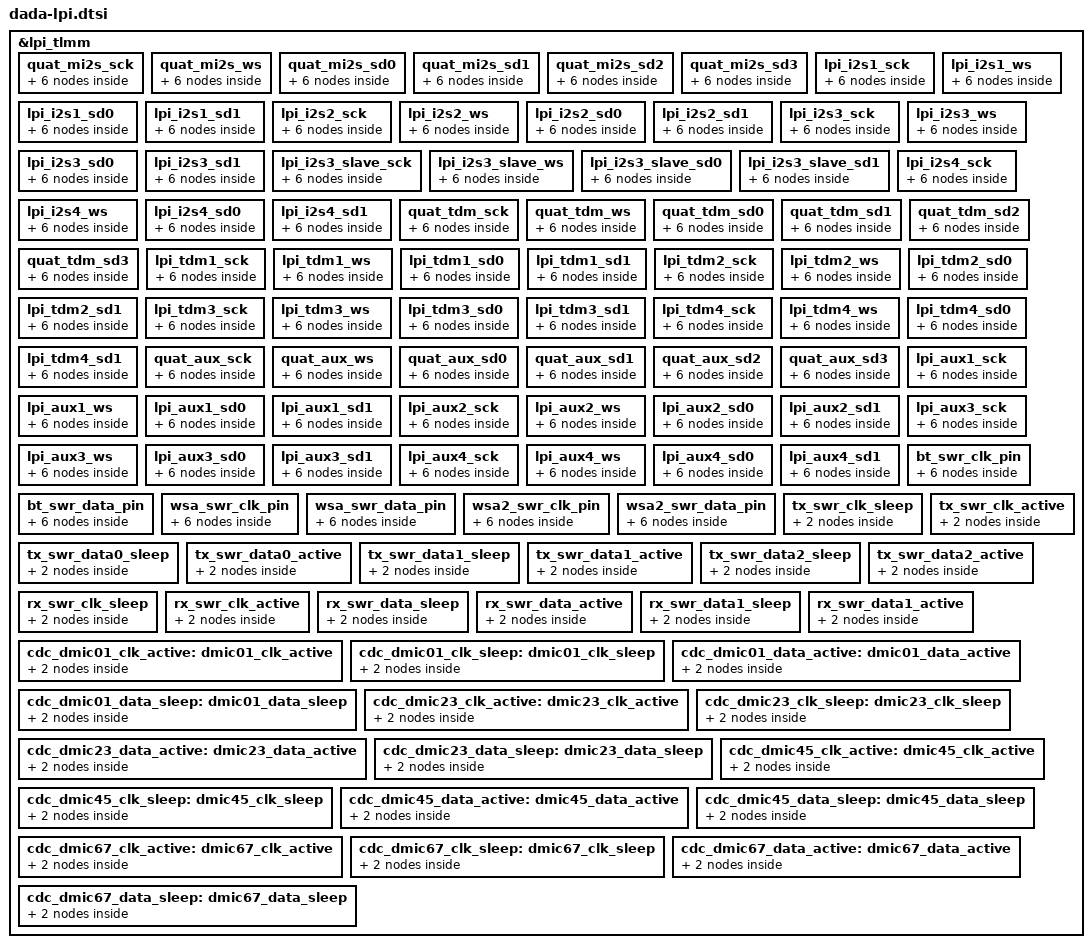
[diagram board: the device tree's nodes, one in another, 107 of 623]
// SPDX-License-Identifier: BSD-3-Clause
/*
 * Copyright (c) 2023-2024 Qualcomm Innovation Center, Inc. All rights reserved.
 * Copyright (c) 2025 The LineageOS Project
 */

&lpi_tlmm {
	quat_mi2s_sck {

		quat_mi2s_sck_sleep: quat_mi2s_sck_sleep {

			mux {
				function = "func2";
				pins = "gpio0";
			};

			config {
				input-enable;
				bias-pull-down;
				drive-strength = <0x02>;
				pins = "gpio0";
			};
		};

		quat_mi2s_sck_active: quat_mi2s_sck_active {

			mux {
				function = "func2";
				pins = "gpio0";
			};

			config {
				output-high;
				bias-disable;
				drive-strength = <0x08>;
				pins = "gpio0";
			};
		};
	};

	quat_mi2s_ws {

		quat_mi2s_ws_sleep: quat_mi2s_ws_sleep {

			mux {
				function = "func2";
				pins = "gpio1";
			};

			config {
				input-enable;
				bias-pull-down;
				drive-strength = <0x02>;
				pins = "gpio1";
			};
		};

		quat_mi2s_ws_active: quat_mi2s_ws_active {

			mux {
				function = "func2";
				pins = "gpio1";
			};

			config {
				output-high;
				bias-disable;
				drive-strength = <0x08>;
				pins = "gpio1";
			};
		};
	};

	quat_mi2s_sd0 {

		quat_mi2s_sd0_sleep: quat_mi2s_sd0_sleep {

			mux {
				function = "func2";
				pins = "gpio2";
			};

			config {
				input-enable;
				bias-pull-down;
				drive-strength = <0x02>;
				pins = "gpio2";
			};
		};

		quat_mi2s_sd0_active: quat_mi2s_sd0_active {

			mux {
				function = "func2";
				pins = "gpio2";
			};

			config {
				output-high;
				bias-disable;
				drive-strength = <0x08>;
				pins = "gpio2";
			};
		};
	};

	quat_mi2s_sd1 {

		quat_mi2s_sd1_sleep: quat_mi2s_sd1_sleep {

			mux {
				function = "func2";
				pins = "gpio3";
			};

			config {
				input-enable;
				bias-pull-down;
				drive-strength = <0x02>;
				pins = "gpio3";
			};
		};

		quat_mi2s_sd1_active: quat_mi2s_sd1_active {

			mux {
				function = "func2";
				pins = "gpio3";
			};

			config {
				output-high;
				bias-disable;
				drive-strength = <0x08>;
				pins = "gpio3";
			};
		};
	};

	quat_mi2s_sd2 {

		quat_mi2s_sd2_sleep: quat_mi2s_sd2_sleep {

			mux {
				function = "func2";
				pins = "gpio4";
			};

			config {
				input-enable;
				bias-pull-down;
				drive-strength = <0x02>;
				pins = "gpio4";
			};
		};

		quat_mi2s_sd2_active: quat_mi2s_sd2_active {

			mux {
				function = "func2";
				pins = "gpio4";
			};

			config {
				output-high;
				bias-disable;
				drive-strength = <0x08>;
				pins = "gpio4";
			};
		};
	};

	quat_mi2s_sd3 {

		quat_mi2s_sd3_sleep: quat_mi2s_sd3_sleep {

			mux {
				function = "func3";
				pins = "gpio5";
			};

			config {
				input-enable;
				bias-pull-down;
				drive-strength = <0x02>;
				pins = "gpio5";
			};
		};

		quat_mi2s_sd3_active: quat_mi2s_sd3_active {

			mux {
				function = "func3";
				pins = "gpio5";
			};

			config {
				output-high;
				bias-disable;
				drive-strength = <0x08>;
				pins = "gpio5";
			};
		};
	};

	lpi_i2s1_sck {

		lpi_i2s1_sck_sleep: lpi_i2s1_sck_sleep {

			mux {
				function = "func2";
				pins = "gpio6";
			};

			config {
				input-enable;
				bias-pull-down;
				drive-strength = <0x02>;
				pins = "gpio6";
			};
		};

		lpi_i2s1_sck_active: lpi_i2s1_sck_active {

			mux {
				function = "func2";
				pins = "gpio6";
			};

			config {
				output-high;
				bias-disable;
				drive-strength = <0x08>;
				pins = "gpio6";
			};
		};
	};

	lpi_i2s1_ws {

		lpi_i2s1_ws_sleep: lpi_i2s1_ws_sleep {

			mux {
				function = "func2";
				pins = "gpio7";
			};

			config {
				input-enable;
				bias-pull-down;
				drive-strength = <0x02>;
				pins = "gpio7";
			};
		};

		lpi_i2s1_ws_active: lpi_i2s1_ws_active {

			mux {
				function = "func2";
				pins = "gpio7";
			};

			config {
				output-high;
				bias-disable;
				drive-strength = <0x08>;
				pins = "gpio7";
			};
		};
	};

	lpi_i2s1_sd0 {

		lpi_i2s1_sd0_sleep: lpi_i2s1_sd0_sleep {

			mux {
				function = "func2";
				pins = "gpio8";
			};

			config {
				input-enable;
				bias-pull-down;
				drive-strength = <0x02>;
				pins = "gpio8";
			};
		};

		lpi_i2s1_sd0_active: lpi_i2s1_sd0_active {

			mux {
				function = "func2";
				pins = "gpio8";
			};

			config {
				output-high;
				bias-disable;
				drive-strength = <0x08>;
				pins = "gpio8";
			};
		};
	};

	lpi_i2s1_sd1 {

		lpi_i2s1_sd1_sleep: lpi_i2s1_sd1_sleep {

			mux {
				function = "func2";
				pins = "gpio9";
			};

			config {
				input-enable;
				bias-pull-down;
				drive-strength = <0x02>;
				pins = "gpio9";
			};
		};

		lpi_i2s1_sd1_active: lpi_i2s1_sd1_active {

			mux {
				function = "func2";
				pins = "gpio9";
			};

			config {
				output-high;
				bias-disable;
				drive-strength = <0x08>;
				pins = "gpio9";
			};
		};
	};

	lpi_i2s2_sck {

		lpi_i2s2_sck_sleep: lpi_i2s2_sck_sleep {

			mux {
				function = "func1";
				pins = "gpio10";
			};

			config {
				input-enable;
				bias-pull-down;
				drive-strength = <0x02>;
				pins = "gpio10";
			};
		};

		lpi_i2s2_sck_active: lpi_i2s2_sck_active {

			mux {
				function = "func1";
				pins = "gpio10";
			};

			config {
				output-high;
				bias-disable;
				drive-strength = <0x08>;
				pins = "gpio10";
			};
		};
	};

	lpi_i2s2_ws {

		lpi_i2s2_ws_sleep: lpi_i2s2_ws_sleep {

			mux {
				function = "func1";
				pins = "gpio11";
			};

			config {
				input-enable;
				bias-pull-down;
				drive-strength = <0x02>;
				pins = "gpio11";
			};
		};

		lpi_i2s2_ws_active: lpi_i2s2_ws_active {

			mux {
				function = "func1";
				pins = "gpio11";
			};

			config {
				output-high;
				bias-disable;
				drive-strength = <0x08>;
				pins = "gpio11";
			};
		};
	};

	lpi_i2s2_sd0 {

		lpi_i2s2_sd0_sleep: lpi_i2s2_sd0_sleep {

			mux {
				function = "func1";
				pins = "gpio15";
			};

			config {
				input-enable;
				bias-pull-down;
				drive-strength = <0x02>;
				pins = "gpio15";
			};
		};

		lpi_i2s2_sd0_active: lpi_i2s2_sd0_active {

			mux {
				function = "func1";
				pins = "gpio15";
			};

			config {
				output-high;
				bias-disable;
				drive-strength = <0x08>;
				pins = "gpio15";
			};
		};
	};

	lpi_i2s2_sd1 {

		lpi_i2s2_sd1_sleep: lpi_i2s2_sd1_sleep {

			mux {
				function = "func1";
				pins = "gpio16";
			};

			config {
				input-enable;
				bias-pull-down;
				drive-strength = <0x02>;
				pins = "gpio16";
			};
		};

		lpi_i2s2_sd1_active: lpi_i2s2_sd1_active {

			mux {
				function = "func1";
				pins = "gpio16";
			};

			config {
				output-high;
				bias-disable;
				drive-strength = <0x08>;
				pins = "gpio16";
			};
		};
	};

	lpi_i2s3_sck {

		lpi_i2s3_sck_sleep: lpi_i2s3_sck_sleep {

			mux {
				function = "func2";
				pins = "gpio12";
			};

			config {
				input-enable;
				bias-pull-down;
				drive-strength = <0x02>;
				pins = "gpio12";
			};
		};

		lpi_i2s3_sck_active: lpi_i2s3_sck_active {

			mux {
				function = "func2";
				pins = "gpio12";
			};

			config {
				output-high;
				bias-disable;
				drive-strength = <0x08>;
				pins = "gpio12";
			};
		};
	};

	lpi_i2s3_ws {

		lpi_i2s3_ws_sleep: lpi_i2s3_ws_sleep {

			mux {
				function = "func2";
				pins = "gpio13";
			};

			config {
				input-enable;
				bias-pull-down;
				drive-strength = <0x02>;
				pins = "gpio13";
			};
		};

		lpi_i2s3_ws_active: lpi_i2s3_ws_active {

			mux {
				function = "func2";
				pins = "gpio13";
			};

			config {
				output-high;
				bias-disable;
				drive-strength = <0x08>;
				pins = "gpio13";
			};
		};
	};

	lpi_i2s3_sd0 {

		lpi_i2s3_sd0_sleep: lpi_i2s3_sd0_sleep {

			mux {
				function = "func2";
				pins = "gpio17";
			};

			config {
				input-enable;
				bias-pull-down;
				drive-strength = <0x02>;
				pins = "gpio17";
			};
		};

		lpi_i2s3_sd0_active: lpi_i2s3_sd0_active {

			mux {
				function = "func2";
				pins = "gpio17";
			};

			config {
				output-high;
				bias-disable;
				drive-strength = <0x08>;
				pins = "gpio17";
			};
		};
	};

	lpi_i2s3_sd1 {

		lpi_i2s3_sd1_sleep: lpi_i2s3_sd1_sleep {

			mux {
				function = "func2";
				pins = "gpio18";
			};

			config {
				input-enable;
				bias-pull-down;
				drive-strength = <0x02>;
				pins = "gpio18";
			};
		};

		lpi_i2s3_sd1_active: lpi_i2s3_sd1_active {

			mux {
				function = "func2";
				pins = "gpio18";
			};

			config {
				output-high;
				bias-disable;
				drive-strength = <0x08>;
				pins = "gpio18";
			};
		};
	};

	lpi_i2s3_slave_sck {

		lpi_i2s3_slave_sck_sleep: lpi_i2s3_slave_sck_sleep {

			mux {
				function = "func2";
				pins = "gpio12";
			};

			config {
				input-enable;
				bias-pull-down;
				drive-strength = <0x02>;
				pins = "gpio12";
			};
		};

		lpi_i2s3_slave_sck_active: lpi_i2s3_slave_sck_active {

			mux {
				function = "func2";
				pins = "gpio12";
			};

			config {
				input-enable;
				bias-disable;
				drive-strength = <0x08>;
				pins = "gpio12";
			};
		};
	};

	lpi_i2s3_slave_ws {

		lpi_i2s3_slave_ws_sleep: lpi_i2s3_slave_ws_sleep {

			mux {
				function = "func2";
				pins = "gpio13";
			};

			config {
				input-enable;
				bias-pull-down;
				drive-strength = <0x02>;
				pins = "gpio13";
			};
		};

		lpi_i2s3_slave_ws_active: lpi_i2s3_slave_ws_active {

			mux {
				function = "func2";
				pins = "gpio13";
			};

			config {
				input-enable;
				bias-disable;
				drive-strength = <0x08>;
				pins = "gpio13";
			};
		};
	};

	lpi_i2s3_slave_sd0 {

		lpi_i2s3_slave_sd0_sleep: lpi_i2s3_slave_sd0_sleep {

			mux {
				function = "func2";
				pins = "gpio17";
			};

			config {
				input-enable;
				bias-pull-down;
				drive-strength = <0x02>;
				pins = "gpio17";
			};
		};

		lpi_i2s3_slave_sd0_active: lpi_i2s3_slave_sd0_active {

			mux {
				function = "func2";
				pins = "gpio17";
			};

			config {
				input-enable;
				bias-disable;
				drive-strength = <0x08>;
				pins = "gpio17";
			};
		};
	};

	lpi_i2s3_slave_sd1 {

		lpi_i2s3_slave_sd1_sleep: lpi_i2s3_slave_sd1_sleep {

			mux {
				function = "func2";
				pins = "gpio18";
			};

			config {
				input-enable;
				bias-pull-down;
				drive-strength = <0x02>;
				pins = "gpio18";
			};
		};

		lpi_i2s3_slave_sd1_active: lpi_i2s3_slave_sd1_active {

			mux {
				function = "func2";
				pins = "gpio18";
			};

			config {
				output-high;
				bias-disable;
				drive-strength = <0x08>;
				pins = "gpio18";
			};
		};
	};

	lpi_i2s4_sck {

		lpi_i2s4_sck_sleep: lpi_i2s4_sck_sleep {

			mux {
				function = "func1";
				pins = "gpio19";
			};

			config {
				input-enable;
				bias-pull-down;
				drive-strength = <0x02>;
				pins = "gpio19";
			};
		};

		lpi_i2s4_sck_active: lpi_i2s4_sck_active {

			mux {
				function = "func1";
				pins = "gpio19";
			};

			config {
				output-high;
				bias-disable;
				drive-strength = <0x08>;
				pins = "gpio19";
			};
		};
	};

	lpi_i2s4_ws {

		lpi_i2s4_ws_sleep: lpi_i2s4_ws_sleep {

			mux {
				function = "func1";
				pins = "gpio20";
			};

			config {
				input-enable;
				bias-pull-down;
				drive-strength = <0x02>;
				pins = "gpio20";
			};
		};

		lpi_i2s4_ws_active: lpi_i2s4_ws_active {

			mux {
				function = "func1";
				pins = "gpio20";
			};

			config {
				output-high;
				bias-disable;
				drive-strength = <0x08>;
				pins = "gpio20";
			};
		};
	};

	lpi_i2s4_sd0 {

		lpi_i2s4_sd0_sleep: lpi_i2s4_sd0_sleep {

			mux {
				function = "func1";
				pins = "gpio21";
			};

			config {
				input-enable;
				bias-pull-down;
				drive-strength = <0x02>;
				pins = "gpio21";
			};
		};

		lpi_i2s4_sd0_active: lpi_i2s4_sd0_active {

			mux {
				function = "func1";
				pins = "gpio21";
			};

			config {
				output-high;
				bias-disable;
				drive-strength = <0x08>;
				pins = "gpio21";
			};
		};
	};

	lpi_i2s4_sd1 {

		lpi_i2s4_sd1_sleep: lpi_i2s4_sd1_sleep {

			mux {
				function = "func1";
				pins = "gpio22";
			};

			config {
				input-enable;
				bias-pull-down;
				drive-strength = <0x02>;
				pins = "gpio22";
			};
		};

		lpi_i2s4_sd1_active: lpi_i2s4_sd1_active {

			mux {
				function = "func1";
				pins = "gpio22";
			};

			config {
				output-high;
				bias-disable;
				drive-strength = <0x08>;
				pins = "gpio22";
			};
		};
	};

	quat_tdm_sck {

		quat_tdm_sck_sleep: quat_tdm_sck_sleep {

			mux {
				function = "func2";
				pins = "gpio0";
			};

			config {
				input-enable;
				bias-pull-down;
				drive-strength = <0x02>;
				pins = "gpio0";
			};
		};

		quat_tdm_sck_active: quat_tdm_sck_active {

			mux {
				function = "func2";
				pins = "gpio0";
			};

			config {
				output-high;
				bias-disable;
				drive-strength = <0x08>;
				pins = "gpio0";
			};
		};
	};

	quat_tdm_ws {

		quat_tdm_ws_sleep: quat_tdm_ws_sleep {

			mux {
				function = "func2";
				pins = "gpio1";
			};

			config {
				input-enable;
				bias-pull-down;
				drive-strength = <0x02>;
				pins = "gpio1";
			};
		};

		quat_tdm_ws_active: quat_tdm_ws_active {

			mux {
				function = "func2";
				pins = "gpio1";
			};

			config {
				output-high;
				bias-disable;
				drive-strength = <0x08>;
				pins = "gpio1";
			};
		};
	};

	quat_tdm_sd0 {

		quat_tdm_sd0_sleep: quat_tdm_sd0_sleep {

			mux {
				function = "func2";
				pins = "gpio2";
			};

			config {
				input-enable;
				bias-pull-down;
				drive-strength = <0x02>;
				pins = "gpio2";
			};
		};

		quat_tdm_sd0_active: quat_tdm_sd0_active {

			mux {
				function = "func2";
				pins = "gpio2";
			};

			config {
				output-high;
				bias-disable;
				drive-strength = <0x08>;
				pins = "gpio2";
			};
		};
	};

	quat_tdm_sd1 {

		quat_tdm_sd1_sleep: quat_tdm_sd1_sleep {

			mux {
				function = "func2";
				pins = "gpio3";
			};

			config {
				input-enable;
				bias-pull-down;
				drive-strength = <0x02>;
				pins = "gpio3";
			};
		};

		quat_tdm_sd1_active: quat_tdm_sd1_active {

			mux {
				function = "func2";
				pins = "gpio3";
			};

			config {
				output-high;
				bias-disable;
				drive-strength = <0x08>;
				pins = "gpio3";
			};
		};
	};

	quat_tdm_sd2 {

		quat_tdm_sd2_sleep: quat_tdm_sd2_sleep {

			mux {
				function = "func2";
				pins = "gpio4";
			};

			config {
				input-enable;
				bias-pull-down;
				drive-strength = <0x02>;
				pins = "gpio4";
			};
		};

		quat_tdm_sd2_active: quat_tdm_sd2_active {

			mux {
				function = "func2";
				pins = "gpio4";
			};

			config {
				output-high;
				bias-disable;
				drive-strength = <0x08>;
				pins = "gpio4";
			};
		};
	};

	quat_tdm_sd3 {

		quat_tdm_sd3_sleep: quat_tdm_sd3_sleep {

			mux {
				function = "func3";
				pins = "gpio5";
			};

			config {
				input-enable;
				bias-pull-down;
				drive-strength = <0x02>;
				pins = "gpio5";
			};
		};

		quat_tdm_sd3_active: quat_tdm_sd3_active {

			mux {
				function = "func3";
				pins = "gpio5";
			};

			config {
				output-high;
				bias-disable;
				drive-strength = <0x08>;
				pins = "gpio5";
			};
		};
	};

	lpi_tdm1_sck {

		lpi_tdm1_sck_sleep: lpi_tdm1_sck_sleep {

			mux {
				function = "func2";
				pins = "gpio6";
			};

			config {
				input-enable;
				bias-pull-down;
				drive-strength = <0x02>;
				pins = "gpio6";
			};
		};

		lpi_tdm1_sck_active: lpi_tdm1_sck_active {

			mux {
				function = "func2";
				pins = "gpio6";
			};

			config {
				output-high;
				bias-disable;
				drive-strength = <0x08>;
				pins = "gpio6";
			};
		};
	};

	lpi_tdm1_ws {

		lpi_tdm1_ws_sleep: lpi_tdm1_ws_sleep {

			mux {
				function = "func2";
				pins = "gpio7";
			};

			config {
				input-enable;
				bias-pull-down;
				drive-strength = <0x02>;
				pins = "gpio7";
			};
		};

		lpi_tdm1_ws_active: lpi_tdm1_ws_active {

			mux {
				function = "func2";
				pins = "gpio7";
			};

			config {
				output-high;
				bias-disable;
				drive-strength = <0x08>;
				pins = "gpio7";
			};
		};
	};

	lpi_tdm1_sd0 {

		lpi_tdm1_sd0_sleep: lpi_tdm1_sd0_sleep {

			mux {
				function = "func2";
				pins = "gpio8";
			};

			config {
				input-enable;
				bias-pull-down;
				drive-strength = <0x02>;
				pins = "gpio8";
			};
		};

		lpi_tdm1_sd0_active: lpi_tdm1_sd0_active {

			mux {
				function = "func2";
				pins = "gpio8";
			};

			config {
				output-high;
				bias-disable;
				drive-strength = <0x08>;
				pins = "gpio8";
			};
		};
	};

	lpi_tdm1_sd1 {

		lpi_tdm1_sd1_sleep: lpi_tdm1_sd1_sleep {

			mux {
				function = "func2";
				pins = "gpio9";
			};

			config {
				input-enable;
				bias-pull-down;
				drive-strength = <0x02>;
				pins = "gpio9";
			};
		};

		lpi_tdm1_sd1_active: lpi_tdm1_sd1_active {

			mux {
				function = "func2";
				pins = "gpio9";
			};

			config {
				output-high;
				bias-disable;
				drive-strength = <0x08>;
				pins = "gpio9";
			};
		};
	};

	lpi_tdm2_sck {

		lpi_tdm2_sck_sleep: lpi_tdm2_sck_sleep {

			mux {
				function = "func1";
				pins = "gpio10";
			};

			config {
				input-enable;
				bias-pull-down;
				drive-strength = <0x02>;
				pins = "gpio10";
			};
		};

		lpi_tdm2_sck_active: lpi_tdm2_sck_active {

			mux {
				function = "func1";
				pins = "gpio10";
			};

			config {
				output-high;
				bias-disable;
				drive-strength = <0x08>;
				pins = "gpio10";
			};
		};
	};

	lpi_tdm2_ws {

		lpi_tdm2_ws_sleep: lpi_tdm2_ws_sleep {

			mux {
				function = "func1";
				pins = "gpio11";
			};

			config {
				input-enable;
				bias-pull-down;
				drive-strength = <0x02>;
				pins = "gpio11";
			};
		};

		lpi_tdm2_ws_active: lpi_tdm2_ws_active {

			mux {
				function = "func1";
				pins = "gpio11";
			};

			config {
				output-high;
				bias-disable;
				drive-strength = <0x08>;
				pins = "gpio11";
			};
		};
	};

	lpi_tdm2_sd0 {

		lpi_tdm2_sd0_sleep: lpi_tdm2_sd0_sleep {

			mux {
				function = "func1";
				pins = "gpio15";
			};

			config {
				input-enable;
				bias-pull-down;
				drive-strength = <0x02>;
				pins = "gpio15";
			};
		};

		lpi_tdm2_sd0_active: lpi_tdm2_sd0_active {

			mux {
				function = "func1";
				pins = "gpio15";
			};

			config {
				output-high;
				bias-disable;
				drive-strength = <0x08>;
				pins = "gpio15";
			};
		};
	};

	lpi_tdm2_sd1 {

		lpi_tdm2_sd1_sleep: lpi_tdm2_sd1_sleep {

			mux {
				function = "func1";
				pins = "gpio16";
			};

			config {
				input-enable;
				bias-pull-down;
				drive-strength = <0x02>;
				pins = "gpio16";
			};
		};

		lpi_tdm2_sd1_active: lpi_tdm2_sd1_active {

			mux {
				function = "func1";
				pins = "gpio16";
			};

			config {
				output-high;
				bias-disable;
				drive-strength = <0x08>;
				pins = "gpio16";
			};
		};
	};

	lpi_tdm3_sck {

		lpi_tdm3_sck_sleep: lpi_tdm3_sck_sleep {

			mux {
				function = "func2";
				pins = "gpio12";
			};

			config {
				input-enable;
				bias-pull-down;
				drive-strength = <0x02>;
				pins = "gpio12";
			};
		};

		lpi_tdm3_sck_active: lpi_tdm3_sck_active {

			mux {
				function = "func2";
				pins = "gpio12";
			};

			config {
				output-high;
				bias-disable;
				drive-strength = <0x08>;
				pins = "gpio12";
			};
		};
	};

	lpi_tdm3_ws {

		lpi_tdm3_ws_sleep: lpi_tdm3_ws_sleep {

			mux {
				function = "func2";
				pins = "gpio13";
			};

			config {
				input-enable;
				bias-pull-down;
				drive-strength = <0x02>;
				pins = "gpio13";
			};
		};

		lpi_tdm3_ws_active: lpi_tdm3_ws_active {

			mux {
				function = "func2";
				pins = "gpio13";
			};

			config {
				output-high;
				bias-disable;
				drive-strength = <0x08>;
				pins = "gpio13";
			};
		};
	};

	lpi_tdm3_sd0 {

		lpi_tdm3_sd0_sleep: lpi_tdm3_sd0_sleep {

			mux {
				function = "func2";
				pins = "gpio17";
			};

			config {
				input-enable;
				bias-pull-down;
				drive-strength = <0x02>;
				pins = "gpio17";
			};
		};

		lpi_tdm3_sd0_active: lpi_tdm3_sd0_active {

			mux {
				function = "func2";
				pins = "gpio17";
			};

			config {
				output-high;
				bias-disable;
				drive-strength = <0x08>;
				pins = "gpio17";
			};
		};
	};

	lpi_tdm3_sd1 {

		lpi_tdm3_sd1_sleep: lpi_tdm3_sd1_sleep {

			mux {
				function = "func2";
				pins = "gpio18";
			};

			config {
				input-enable;
				bias-pull-down;
				drive-strength = <0x02>;
				pins = "gpio18";
			};
		};

		lpi_tdm3_sd1_active: lpi_tdm3_sd1_active {

			mux {
				function = "func2";
				pins = "gpio18";
			};

			config {
				output-high;
				bias-disable;
				drive-strength = <0x08>;
				pins = "gpio18";
			};
		};
	};

	lpi_tdm4_sck {

		lpi_tdm4_sck_sleep: lpi_tdm4_sck_sleep {

			mux {
				function = "func1";
				pins = "gpio19";
			};

			config {
				input-enable;
				bias-pull-down;
				drive-strength = <0x02>;
				pins = "gpio19";
			};
		};

		lpi_tdm4_sck_active: lpi_tdm4_sck_active {

			mux {
				function = "func1";
				pins = "gpio19";
			};

			config {
				output-high;
				bias-disable;
				drive-strength = <0x08>;
				pins = "gpio19";
			};
		};
	};

	lpi_tdm4_ws {

		lpi_tdm4_ws_sleep: lpi_tdm4_ws_sleep {

			mux {
				function = "func1";
				pins = "gpio20";
			};

			config {
				input-enable;
				bias-pull-down;
				drive-strength = <0x02>;
				pins = "gpio20";
			};
		};

		lpi_tdm4_ws_active: lpi_tdm4_ws_active {

			mux {
				function = "func1";
				pins = "gpio20";
			};

			config {
				output-high;
				bias-disable;
				drive-strength = <0x08>;
				pins = "gpio20";
			};
		};
	};

	lpi_tdm4_sd0 {

		lpi_tdm4_sd0_sleep: lpi_tdm4_sd0_sleep {

			mux {
				function = "func1";
				pins = "gpio21";
			};

			config {
				input-enable;
				bias-pull-down;
				drive-strength = <0x02>;
				pins = "gpio21";
			};
		};

		lpi_tdm4_sd0_active: lpi_tdm4_sd0_active {

			mux {
				function = "func1";
				pins = "gpio21";
			};

			config {
				output-high;
				bias-disable;
				drive-strength = <0x08>;
				pins = "gpio21";
			};
		};
	};

	lpi_tdm4_sd1 {

		lpi_tdm4_sd1_sleep: lpi_tdm4_sd1_sleep {

			mux {
				function = "func1";
				pins = "gpio22";
			};

			config {
				input-enable;
				bias-pull-down;
				drive-strength = <0x02>;
				pins = "gpio22";
			};
		};

		lpi_tdm4_sd1_active: lpi_tdm4_sd1_active {

			mux {
				function = "func1";
				pins = "gpio22";
			};

			config {
				output-high;
				bias-disable;
				drive-strength = <0x08>;
				pins = "gpio22";
			};
		};
	};

	quat_aux_sck {

		quat_aux_sck_sleep: quat_aux_sck_sleep {

			mux {
				function = "func2";
				pins = "gpio0";
			};

			config {
				input-enable;
				bias-pull-down;
				drive-strength = <0x02>;
				pins = "gpio0";
			};
		};

		quat_aux_sck_active: quat_aux_sck_active {

			mux {
				function = "func2";
				pins = "gpio0";
			};

			config {
				output-high;
				bias-disable;
				drive-strength = <0x08>;
				pins = "gpio0";
			};
		};
	};

	quat_aux_ws {

		quat_aux_ws_sleep: quat_aux_ws_sleep {

			mux {
				function = "func2";
				pins = "gpio1";
			};

			config {
				input-enable;
				bias-pull-down;
				drive-strength = <0x02>;
				pins = "gpio1";
			};
		};

		quat_aux_ws_active: quat_aux_ws_active {

			mux {
				function = "func2";
				pins = "gpio1";
			};

			config {
				output-high;
				bias-disable;
				drive-strength = <0x08>;
				pins = "gpio1";
			};
		};
	};

	quat_aux_sd0 {

		quat_aux_sd0_sleep: quat_aux_sd0_sleep {

			mux {
				function = "func2";
				pins = "gpio2";
			};

			config {
				input-enable;
				bias-pull-down;
				drive-strength = <0x02>;
				pins = "gpio2";
			};
		};

		quat_aux_sd0_active: quat_aux_sd0_active {

			mux {
				function = "func2";
				pins = "gpio2";
			};

			config {
				output-high;
				bias-disable;
				drive-strength = <0x08>;
				pins = "gpio2";
			};
		};
	};

	quat_aux_sd1 {

		quat_aux_sd1_sleep: quat_aux_sd1_sleep {

			mux {
				function = "func2";
				pins = "gpio3";
			};

			config {
				input-enable;
				bias-pull-down;
				drive-strength = <0x02>;
				pins = "gpio3";
			};
		};

		quat_aux_sd1_active: quat_aux_sd1_active {

			mux {
				function = "func2";
				pins = "gpio3";
			};

			config {
				output-high;
				bias-disable;
				drive-strength = <0x08>;
				pins = "gpio3";
			};
		};
	};

	quat_aux_sd2 {

		quat_aux_sd2_sleep: quat_aux_sd2_sleep {

			mux {
				function = "func2";
				pins = "gpio4";
			};

			config {
				input-enable;
				bias-pull-down;
				drive-strength = <0x02>;
				pins = "gpio4";
			};
		};

		quat_aux_sd2_active: quat_aux_sd2_active {

			mux {
				function = "func2";
				pins = "gpio4";
			};

			config {
				output-high;
				bias-disable;
				drive-strength = <0x08>;
				pins = "gpio4";
			};
		};
	};

	quat_aux_sd3 {

		quat_aux_sd3_sleep: quat_aux_sd3_sleep {

			mux {
				function = "func3";
				pins = "gpio5";
			};

			config {
				input-enable;
				bias-pull-down;
				drive-strength = <0x02>;
				pins = "gpio5";
			};
		};

		quat_aux_sd3_active: quat_aux_sd3_active {

			mux {
				function = "func3";
				pins = "gpio5";
			};

			config {
				output-high;
				bias-disable;
				drive-strength = <0x08>;
				pins = "gpio5";
			};
		};
	};

	lpi_aux1_sck {

		lpi_aux1_sck_sleep: lpi_aux1_sck_sleep {

			mux {
				function = "func2";
				pins = "gpio6";
			};

			config {
				input-enable;
				bias-pull-down;
				drive-strength = <0x02>;
				pins = "gpio6";
			};
		};

		lpi_aux1_sck_active: lpi_aux1_sck_active {

			mux {
				function = "func2";
				pins = "gpio6";
			};

			config {
				output-high;
				bias-disable;
				drive-strength = <0x08>;
				pins = "gpio6";
			};
		};
	};

	lpi_aux1_ws {

		lpi_aux1_ws_sleep: lpi_aux1_ws_sleep {

			mux {
				function = "func2";
				pins = "gpio7";
			};

			config {
				input-enable;
				bias-pull-down;
				drive-strength = <0x02>;
				pins = "gpio7";
			};
		};

		lpi_aux1_ws_active: lpi_aux1_ws_active {

			mux {
				function = "func2";
				pins = "gpio7";
			};

			config {
				output-high;
				bias-disable;
				drive-strength = <0x08>;
				pins = "gpio7";
			};
		};
	};

	lpi_aux1_sd0 {

		lpi_aux1_sd0_sleep: lpi_aux1_sd0_sleep {

			mux {
				function = "func2";
				pins = "gpio8";
			};

			config {
				input-enable;
				bias-pull-down;
				drive-strength = <0x02>;
				pins = "gpio8";
			};
		};

		lpi_aux1_sd0_active: lpi_aux1_sd0_active {

			mux {
				function = "func2";
				pins = "gpio8";
			};

			config {
				output-high;
				bias-disable;
				drive-strength = <0x08>;
				pins = "gpio8";
			};
		};
	};

	lpi_aux1_sd1 {

		lpi_aux1_sd1_sleep: lpi_aux1_sd1_sleep {

			mux {
				function = "func2";
				pins = "gpio9";
			};

			config {
				input-enable;
				bias-pull-down;
				drive-strength = <0x02>;
				pins = "gpio9";
			};
		};

		lpi_aux1_sd1_active: lpi_aux1_sd1_active {

			mux {
				function = "func2";
				pins = "gpio9";
			};

			config {
				output-high;
				bias-disable;
				drive-strength = <0x08>;
				pins = "gpio9";
			};
		};
	};

	lpi_aux2_sck {

		lpi_aux2_sck_sleep: lpi_aux2_sck_sleep {

			mux {
				function = "func1";
				pins = "gpio10";
			};

			config {
				input-enable;
				bias-pull-down;
				drive-strength = <0x02>;
				pins = "gpio10";
			};
		};

		lpi_aux2_sck_active: lpi_aux2_sck_active {

			mux {
				function = "func1";
				pins = "gpio10";
			};

			config {
				output-high;
				bias-disable;
				drive-strength = <0x08>;
				pins = "gpio10";
			};
		};
	};

	lpi_aux2_ws {

		lpi_aux2_ws_sleep: lpi_aux2_ws_sleep {

			mux {
				function = "func1";
				pins = "gpio11";
			};

			config {
				input-enable;
				bias-pull-down;
				drive-strength = <0x02>;
				pins = "gpio11";
			};
		};

		lpi_aux2_ws_active: lpi_aux2_ws_active {

			mux {
				function = "func1";
				pins = "gpio11";
			};

			config {
				output-high;
				bias-disable;
				drive-strength = <0x08>;
				pins = "gpio11";
			};
		};
	};

	lpi_aux2_sd0 {

		lpi_aux2_sd0_sleep: lpi_aux2_sd0_sleep {

			mux {
				function = "func1";
				pins = "gpio15";
			};

			config {
				input-enable;
				bias-pull-down;
				drive-strength = <0x02>;
				pins = "gpio15";
			};
		};

		lpi_aux2_sd0_active: lpi_aux2_sd0_active {

			mux {
				function = "func1";
				pins = "gpio15";
			};

			config {
				output-high;
				bias-disable;
				drive-strength = <0x08>;
				pins = "gpio15";
			};
		};
	};

	lpi_aux2_sd1 {

		lpi_aux2_sd1_sleep: lpi_aux2_sd1_sleep {

			mux {
				function = "func1";
				pins = "gpio16";
			};

			config {
				input-enable;
				bias-pull-down;
				drive-strength = <0x02>;
				pins = "gpio16";
			};
		};

		lpi_aux2_sd1_active: lpi_aux2_sd1_active {

			mux {
				function = "func1";
				pins = "gpio16";
			};

			config {
				output-high;
				bias-disable;
				drive-strength = <0x08>;
				pins = "gpio16";
			};
		};
	};

	lpi_aux3_sck {

		lpi_aux3_sck_sleep: lpi_aux3_sck_sleep {

			mux {
				function = "func2";
				pins = "gpio12";
			};

			config {
				input-enable;
				bias-pull-down;
				drive-strength = <0x02>;
				pins = "gpio12";
			};
		};

		lpi_aux3_sck_active: lpi_aux3_sck_active {

			mux {
				function = "func2";
				pins = "gpio12";
			};

			config {
				output-high;
				bias-disable;
				drive-strength = <0x08>;
				pins = "gpio12";
			};
		};
	};

	lpi_aux3_ws {

		lpi_aux3_ws_sleep: lpi_aux3_ws_sleep {

			mux {
				function = "func2";
				pins = "gpio13";
			};

			config {
				input-enable;
				bias-pull-down;
				drive-strength = <0x02>;
				pins = "gpio13";
			};
		};

		lpi_aux3_ws_active: lpi_aux3_ws_active {

			mux {
				function = "func2";
				pins = "gpio13";
			};

			config {
				output-high;
				bias-disable;
				drive-strength = <0x08>;
				pins = "gpio13";
			};
		};
	};

	lpi_aux3_sd0 {

		lpi_aux3_sd0_sleep: lpi_aux3_sd0_sleep {

			mux {
				function = "func2";
				pins = "gpio17";
			};

			config {
				input-enable;
				bias-pull-down;
				drive-strength = <0x02>;
				pins = "gpio17";
			};
		};

		lpi_aux3_sd0_active: lpi_aux3_sd0_active {

			mux {
				function = "func2";
				pins = "gpio17";
			};

			config {
				output-high;
				bias-disable;
				drive-strength = <0x08>;
				pins = "gpio17";
			};
		};
	};

	lpi_aux3_sd1 {

		lpi_aux3_sd1_sleep: lpi_aux3_sd1_sleep {

			mux {
				function = "func2";
				pins = "gpio18";
			};

			config {
				input-enable;
				bias-pull-down;
				drive-strength = <0x02>;
				pins = "gpio18";
			};
		};

		lpi_aux3_sd1_active: lpi_aux3_sd1_active {

			mux {
				function = "func2";
				pins = "gpio18";
			};

			config {
				output-high;
				bias-disable;
				drive-strength = <0x08>;
				pins = "gpio18";
			};
		};
	};

	lpi_aux4_sck {

		lpi_aux4_sck_sleep: lpi_aux4_sck_sleep {

			mux {
				function = "func1";
				pins = "gpio19";
			};

			config {
				input-enable;
				bias-pull-down;
				drive-strength = <0x02>;
				pins = "gpio19";
			};
		};

		lpi_aux4_sck_active: lpi_aux4_sck_active {

			mux {
				function = "func1";
				pins = "gpio19";
			};

			config {
				output-high;
				bias-disable;
				drive-strength = <0x08>;
				pins = "gpio19";
			};
		};
	};

	lpi_aux4_ws {

		lpi_aux4_ws_sleep: lpi_aux4_ws_sleep {

			mux {
				function = "func1";
				pins = "gpio20";
			};

			config {
				input-enable;
				bias-pull-down;
				drive-strength = <0x02>;
				pins = "gpio20";
			};
		};

		lpi_aux4_ws_active: lpi_aux4_ws_active {

			mux {
				function = "func1";
				pins = "gpio20";
			};

			config {
				output-high;
				bias-disable;
				drive-strength = <0x08>;
				pins = "gpio20";
			};
		};
	};

	lpi_aux4_sd0 {

		lpi_aux4_sd0_sleep: lpi_aux4_sd0_sleep {

			mux {
				function = "func1";
				pins = "gpio21";
			};

			config {
				input-enable;
				bias-pull-down;
				drive-strength = <0x02>;
				pins = "gpio21";
			};
		};

		lpi_aux4_sd0_active: lpi_aux4_sd0_active {

			mux {
				function = "func1";
				pins = "gpio21";
			};

			config {
				output-high;
				bias-disable;
				drive-strength = <0x08>;
				pins = "gpio21";
			};
		};
	};

	lpi_aux4_sd1 {

		lpi_aux4_sd1_sleep: lpi_aux4_sd1_sleep {

			mux {
				function = "func1";
				pins = "gpio22";
			};

			config {
				input-enable;
				bias-pull-down;
				drive-strength = <0x02>;
				pins = "gpio22";
			};
		};

		lpi_aux4_sd1_active: lpi_aux4_sd1_active {

			mux {
				function = "func1";
				pins = "gpio22";
			};

			config {
				output-high;
				bias-disable;
				drive-strength = <0x08>;
				pins = "gpio22";
			};
		};
	};

	bt_swr_clk_pin {

		bt_swr_clk_sleep: bt_swr_clk_sleep {

			mux {
				function = "func3";
				pins = "gpio19";
			};

			config {
				bias-pull-down;
				input-enable;
				drive-strength = <0x02>;
				pins = "gpio19";
			};
		};

		bt_swr_clk_active: bt_swr_clk_active {

			mux {
				function = "func3";
				pins = "gpio19";
			};

			config {
				bias-disable;
				slew-rate = <0x01>;
				drive-strength = <0x02>;
				pins = "gpio19";
			};
		};
	};

	bt_swr_data_pin {

		bt_swr_data_sleep: bt_swr_data_sleep {

			mux {
				function = "func3";
				pins = "gpio20";
			};

			config {
				bias-pull-down;
				input-enable;
				drive-strength = <0x02>;
				pins = "gpio20";
			};
		};

		bt_swr_data_active: bt_swr_data_active {

			mux {
				function = "func3";
				pins = "gpio20";
			};

			config {
				bias-bus-hold;
				slew-rate = <0x01>;
				drive-strength = <0x02>;
				pins = "gpio20";
			};
		};
	};

	wsa_swr_clk_pin {

		wsa_swr_clk_sleep: wsa_swr_clk_sleep {

			mux {
				function = "func2";
				pins = "gpio10";
			};

			config {
				bias-pull-down;
				input-enable;
				drive-strength = <0x02>;
				pins = "gpio10";
			};
		};

		wsa_swr_clk_active: wsa_swr_clk_active {

			mux {
				function = "func2";
				pins = "gpio10";
			};

			config {
				bias-disable;
				slew-rate = <0x01>;
				drive-strength = <0x02>;
				pins = "gpio10";
			};
		};
	};

	wsa_swr_data_pin {

		wsa_swr_data_sleep: wsa_swr_data_sleep {

			mux {
				function = "func2";
				pins = "gpio11";
			};

			config {
				bias-pull-down;
				input-enable;
				drive-strength = <0x02>;
				pins = "gpio11";
			};
		};

		wsa_swr_data_active: wsa_swr_data_active {

			mux {
				function = "func2";
				pins = "gpio11";
			};

			config {
				bias-bus-hold;
				slew-rate = <0x01>;
				drive-strength = <0x02>;
				pins = "gpio11";
			};
		};
	};

	wsa2_swr_clk_pin {

		wsa2_swr_clk_sleep: wsa2_swr_clk_sleep {

			mux {
				function = "func2";
				pins = "gpio15";
			};

			config {
				bias-pull-down;
				input-enable;
				drive-strength = <0x02>;
				pins = "gpio15";
			};
		};

		wsa2_swr_clk_active: wsa2_swr_clk_active {

			mux {
				function = "func2";
				pins = "gpio15";
			};

			config {
				bias-disable;
				slew-rate = <0x01>;
				drive-strength = <0x02>;
				pins = "gpio15";
			};
		};
	};

	wsa2_swr_data_pin {

		wsa2_swr_data_sleep: wsa2_swr_data_sleep {

			mux {
				function = "func2";
				pins = "gpio16";
			};

			config {
				bias-pull-down;
				input-enable;
				drive-strength = <0x02>;
				pins = "gpio16";
			};
		};

		wsa2_swr_data_active: wsa2_swr_data_active {

			mux {
				function = "func2";
				pins = "gpio16";
			};

			config {
				bias-bus-hold;
				slew-rate = <0x01>;
				drive-strength = <0x02>;
				pins = "gpio16";
			};
		};
	};

	tx_swr_clk_sleep: tx_swr_clk_sleep {

		mux {
			bias-pull-down;
			input-enable;
			function = "func1";
			pins = "gpio0";
		};

		config {
			drive-strength = <0x02>;
			pins = "gpio0";
		};
	};

	tx_swr_clk_active: tx_swr_clk_active {

		mux {
			function = "func1";
			pins = "gpio0";
		};

		config {
			bias-disable;
			slew-rate = <0x01>;
			drive-strength = <0x04>;
			pins = "gpio0";
		};
	};

	tx_swr_data0_sleep: tx_swr_data0_sleep {

		mux {
			function = "func1";
			pins = "gpio1";
		};

		config {
			bias-bus-hold;
			input-enable;
			drive-strength = <0x02>;
			pins = "gpio1";
		};
	};

	tx_swr_data0_active: tx_swr_data0_active {

		mux {
			function = "func1";
			pins = "gpio1";
		};

		config {
			bias-bus-hold;
			slew-rate = <0x01>;
			drive-strength = <0x04>;
			pins = "gpio1";
		};
	};

	tx_swr_data1_sleep: tx_swr_data1_sleep {

		mux {
			function = "func1";
			pins = "gpio2";
		};

		config {
			bias-pull-down;
			input-enable;
			drive-strength = <0x02>;
			pins = "gpio2";
		};
	};

	tx_swr_data1_active: tx_swr_data1_active {

		mux {
			function = "func1";
			pins = "gpio2";
		};

		config {
			bias-bus-hold;
			slew-rate = <0x01>;
			drive-strength = <0x04>;
			pins = "gpio2";
		};
	};

	tx_swr_data2_sleep: tx_swr_data2_sleep {

		mux {
			function = "func1";
			pins = "gpio14";
		};

		config {
			bias-pull-down;
			input-enable;
			drive-strength = <0x02>;
			pins = "gpio14";
		};
	};

	tx_swr_data2_active: tx_swr_data2_active {

		mux {
			function = "func1";
			pins = "gpio14";
		};

		config {
			bias-bus-hold;
			slew-rate = <0x01>;
			drive-strength = <0x04>;
			pins = "gpio14";
		};
	};

	rx_swr_clk_sleep: rx_swr_clk_sleep {

		mux {
			function = "func1";
			pins = "gpio3";
		};

		config {
			bias-pull-down;
			input-enable;
			drive-strength = <0x02>;
			pins = "gpio3";
		};
	};

	rx_swr_clk_active: rx_swr_clk_active {

		mux {
			function = "func1";
			pins = "gpio3";
		};

		config {
			bias-disable;
			slew-rate = <0x01>;
			drive-strength = <0x02>;
			pins = "gpio3";
		};
	};

	rx_swr_data_sleep: rx_swr_data_sleep {

		mux {
			function = "func1";
			pins = "gpio4";
		};

		config {
			bias-pull-down;
			input-enable;
			drive-strength = <0x02>;
			pins = "gpio4";
		};
	};

	rx_swr_data_active: rx_swr_data_active {

		mux {
			function = "func1";
			pins = "gpio4";
		};

		config {
			bias-bus-hold;
			slew-rate = <0x01>;
			drive-strength = <0x02>;
			pins = "gpio4";
		};
	};

	rx_swr_data1_sleep: rx_swr_data1_sleep {

		mux {
			function = "func1";
			pins = "gpio5";
		};

		config {
			bias-pull-down;
			input-enable;
			drive-strength = <0x02>;
			pins = "gpio5";
		};
	};

	rx_swr_data1_active: rx_swr_data1_active {

		mux {
			function = "func1";
			pins = "gpio5";
		};

		config {
			bias-bus-hold;
			slew-rate = <0x01>;
			drive-strength = <0x02>;
			pins = "gpio5";
		};
	};

	cdc_dmic01_clk_active: dmic01_clk_active {

		mux {
			function = "func1";
			pins = "gpio6";
		};

		config {
			output-high;
			drive-strength = <0x08>;
			pins = "gpio6";
		};
	};

	cdc_dmic01_clk_sleep: dmic01_clk_sleep {

		mux {
			function = "func1";
			pins = "gpio6";
		};

		config {
			output-low;
			bias-disable;
			drive-strength = <0x02>;
			pins = "gpio6";
		};
	};

	cdc_dmic01_data_active: dmic01_data_active {

		mux {
			function = "func1";
			pins = "gpio7";
		};

		config {
			input-enable;
			drive-strength = <0x08>;
			pins = "gpio7";
		};
	};

	cdc_dmic01_data_sleep: dmic01_data_sleep {

		mux {
			function = "func1";
			pins = "gpio7";
		};

		config {
			input-enable;
			pull-down;
			drive-strength = <0x02>;
			pins = "gpio7";
		};
	};

	cdc_dmic23_clk_active: dmic23_clk_active {

		mux {
			function = "func1";
			pins = "gpio8";
		};

		config {
			output-high;
			drive-strength = <0x08>;
			pins = "gpio8";
		};
	};

	cdc_dmic23_clk_sleep: dmic23_clk_sleep {

		mux {
			function = "func1";
			pins = "gpio8";
		};

		config {
			output-low;
			bias-disable;
			drive-strength = <0x02>;
			pins = "gpio8";
		};
	};

	cdc_dmic23_data_active: dmic23_data_active {

		mux {
			function = "func1";
			pins = "gpio9";
		};

		config {
			input-enable;
			drive-strength = <0x08>;
			pins = "gpio9";
		};
	};

	cdc_dmic23_data_sleep: dmic23_data_sleep {

		mux {
			function = "func1";
			pins = "gpio9";
		};

		config {
			input-enable;
			pull-down;
			drive-strength = <0x02>;
			pins = "gpio9";
		};
	};

	cdc_dmic45_clk_active: dmic45_clk_active {

		mux {
			function = "func1";
			pins = "gpio12";
		};

		config {
			output-high;
			drive-strength = <0x08>;
			pins = "gpio12";
		};
	};

	cdc_dmic45_clk_sleep: dmic45_clk_sleep {

		mux {
			function = "func1";
			pins = "gpio12";
		};

		config {
			output-low;
			bias-disable;
			drive-strength = <0x02>;
			pins = "gpio12";
		};
	};

	cdc_dmic45_data_active: dmic45_data_active {

		mux {
			function = "func1";
			pins = "gpio13";
		};

		config {
			input-enable;
			drive-strength = <0x08>;
			pins = "gpio13";
		};
	};

	cdc_dmic45_data_sleep: dmic45_data_sleep {

		mux {
			function = "func1";
			pins = "gpio13";
		};

		config {
			input-enable;
			pull-down;
			drive-strength = <0x02>;
			pins = "gpio13";
		};
	};

	cdc_dmic67_clk_active: dmic67_clk_active {

		mux {
			function = "func1";
			pins = "gpio17";
		};

		config {
			output-high;
			drive-strength = <0x08>;
			pins = "gpio17";
		};
	};

	cdc_dmic67_clk_sleep: dmic67_clk_sleep {

		mux {
			function = "func1";
			pins = "gpio17";
		};

		config {
			output-low;
			bias-disable;
			drive-strength = <0x02>;
			pins = "gpio17";
		};
	};

	cdc_dmic67_data_active: dmic67_data_active {

		mux {
			function = "func1";
			pins = "gpio18";
		};

		config {
			input-enable;
			drive-strength = <0x08>;
			pins = "gpio18";
		};
	};

	cdc_dmic67_data_sleep: dmic67_data_sleep {

		mux {
			function = "func1";
			pins = "gpio18";
		};

		config {
			input-enable;
			pull-down;
			drive-strength = <0x02>;
			pins = "gpio18";
		};
	};
};
